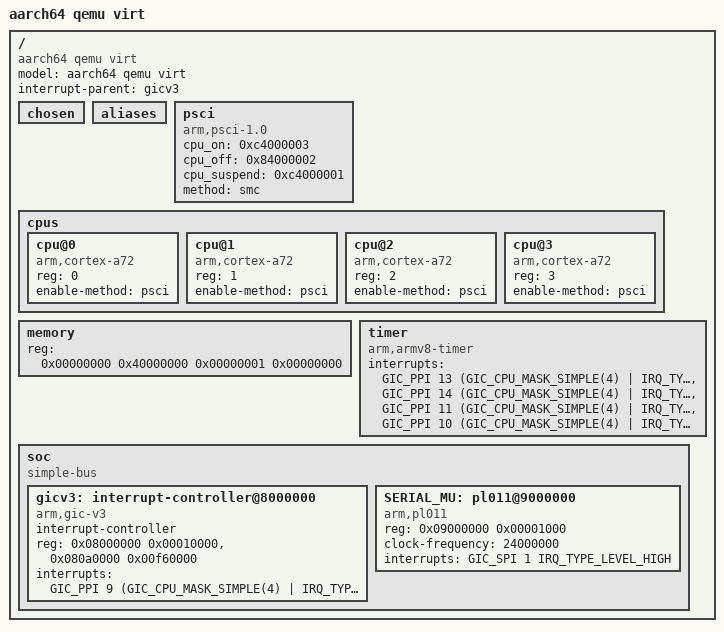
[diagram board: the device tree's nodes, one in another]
#include <dt-bindings/interrupt-controller/arm-gic.h>

/memreserve/ 0x80000000 0x00008000;

/ {
	#address-cells = <2>;
	#size-cells = <2>;
	compatible = "aarch64 qemu virt";
	model = "aarch64 qemu virt";
	interrupt-parent = <&gicv3>;

	chosen { };
	aliases { };

	psci {
		cpu_on = <0xc4000003>;
		cpu_off = <0x84000002>;
		cpu_suspend = <0xc4000001>;
		method = "smc";
		compatible = "arm,psci-1.0", "arm,psci-0.2", "arm,psci";
	};

	cpus {
		#address-cells = <1>;
		#size-cells = <0>;

		cpu@0 {
			device_type = "cpu";
			compatible = "arm,cortex-a72";
			reg = <0>;
			enable-method = "psci";
		};

		cpu@1 {
			device_type = "cpu";
			compatible = "arm,cortex-a72";
			reg = <1>;
			enable-method = "psci";
		};

		cpu@2 {
			device_type = "cpu";
			compatible = "arm,cortex-a72";
			reg = <2>;
			enable-method = "psci";
		};

		cpu@3 {
			device_type = "cpu";
			compatible = "arm,cortex-a72";
			reg = <3>;
			enable-method = "psci";
		};
	};

	memory {
		device_type = "memory";
		reg = <0x00000000 0x40000000 0x00000001 0x00000000>; /* 1 GB */
	};

	timer { /* Generic Timer */
		compatible = "arm,armv8-timer";
		interrupts = <GIC_PPI 13 (GIC_CPU_MASK_SIMPLE(4) |
					  IRQ_TYPE_LEVEL_LOW)>,
			     <GIC_PPI 14 (GIC_CPU_MASK_SIMPLE(4) |
					  IRQ_TYPE_LEVEL_LOW)>,
			     <GIC_PPI 11 (GIC_CPU_MASK_SIMPLE(4) |
					  IRQ_TYPE_LEVEL_LOW)>,
			     <GIC_PPI 10 (GIC_CPU_MASK_SIMPLE(4) |
					  IRQ_TYPE_LEVEL_LOW)>;
	};

	soc: soc {
		#address-cells = <1>;
		#size-cells = <1>;
		compatible = "simple-bus";

		gicv3: interrupt-controller@8000000 {
			interrupt-controller;
			#interrupt-cells = <0x00000003>;
			compatible = "arm,gic-v3";
			reg = <0x08000000 0x00010000>,
			      <0x080a0000 0x00f60000>;
			interrupts = <GIC_PPI 9 (GIC_CPU_MASK_SIMPLE(4) |
						 IRQ_TYPE_LEVEL_HIGH)>;
		};

		SERIAL_MU: pl011@9000000 {
			compatible = "arm,pl011";
			reg = <0x09000000 0x00001000>;
			clock-frequency = <24000000>;
			interrupts = <GIC_SPI 1 IRQ_TYPE_LEVEL_HIGH>;
		};
	};
};
